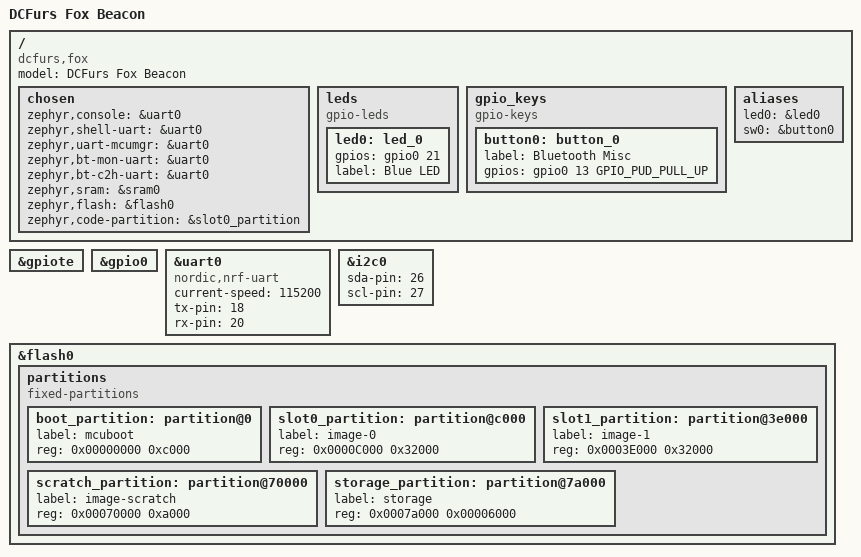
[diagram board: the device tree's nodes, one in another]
/*
 * Copyright (c) 2019 DEFCON Furs
 *
 * SPDX-License-Identifier: Apache-2.0
 */

/dts-v1/;
#include <nordic/nrf52832_qfaa.dtsi>

/ {
	model = "DCFurs Fox Beacon";
	compatible = "dcfurs,fox", "fanstel,bt832",
		"nordic,nrf52832-qfaa", "nordic,nrf52832";

	chosen {
		zephyr,console = &uart0;
		zephyr,shell-uart = &uart0;
		zephyr,uart-mcumgr = &uart0;
		zephyr,bt-mon-uart = &uart0;
		zephyr,bt-c2h-uart = &uart0;
		zephyr,sram = &sram0;
		zephyr,flash = &flash0;
		zephyr,code-partition = &slot0_partition;
	};

	leds {
		compatible = "gpio-leds";
		led0: led_0 {
			gpios = <&gpio0 21 GPIO_INT_ACTIVE_HIGH>;
			label = "Blue LED";
		};
	};

	gpio_keys {
		compatible = "gpio-keys";
		button0: button_0 {
			label = "Bluetooth Misc";
			gpios = <&gpio0 13 GPIO_PUD_PULL_UP>;
		};
	};

	/* These aliases are provided for compatibility with samples */
	aliases {
		led0 = &led0;
		sw0 = &button0;
	};
};

&gpiote {
	status = "okay";
};

&gpio0 {
	status = "okay";
};

&uart0 {
	status = "okay";
	compatible = "nordic,nrf-uart";
	current-speed = <115200>;
	tx-pin = <18>;
	rx-pin = <20>;
};

&i2c0 {
	status = "okay";
	sda-pin = <26>;
	scl-pin = <27>;
};

&flash0 {
	/*
	 * For more information, see:
	 * http://docs.zephyrproject.org/latest/guides/dts/index.html#flash-partitions
	 */
	partitions {
		compatible = "fixed-partitions";
		#address-cells = <1>;
		#size-cells = <1>;

		boot_partition: partition@0 {
			label = "mcuboot";
			reg = <0x00000000 0xc000>;
		};
		slot0_partition: partition@c000 {
			label = "image-0";
			reg = <0x0000C000 0x32000>;
		};
		slot1_partition: partition@3e000 {
			label = "image-1";
			reg = <0x0003E000 0x32000>;
		};
		scratch_partition: partition@70000 {
			label = "image-scratch";
			reg = <0x00070000 0xa000>;
		};
		storage_partition: partition@7a000 {
			label = "storage";
			reg = <0x0007a000 0x00006000>;
		};
	};
};
